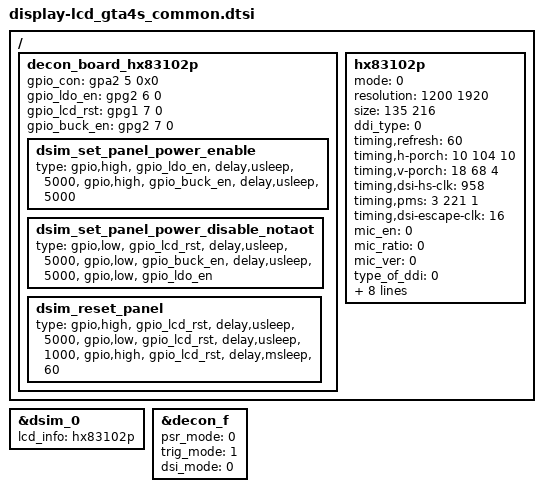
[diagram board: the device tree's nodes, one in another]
/*
 * SAMSUNG LCD Panel Device Tree Source
 *
 * Copyright (c) Samsung Electronics Co., Ltd.
 *		http://www.samsung.com
 *
 * This program is free software; you can redistribute it and/or modify
 * it under the terms of the GNU General Public License version 2 as
 * published by the Free Software Foundation.
 */

/ {
	fragment@lcd {
		target-path = "/";
		__overlay__ {
			decon_board_hx83102p: decon_board_hx83102p {
				gpio_con = <&gpa2 5 0x0>;	/* LCD_CON_DET */

				gpio_ldo_en = <&gpg2 6 0>;
				gpio_lcd_rst = <&gpg1 7 0>;
				gpio_buck_en = <&gpg2 7 0>;

				dsim_set_panel_power_enable {
					type =
					"gpio,high",	"gpio_ldo_en",
					"delay,usleep",	"5000",
					"gpio,high",	"gpio_buck_en",
					"delay,usleep",	"5000";
				};
				dsim_set_panel_power_disable_notaot {
					type =
					"gpio,low",	"gpio_lcd_rst",
					"delay,usleep",	"5000",
					"gpio,low",	"gpio_buck_en",
					"delay,usleep",	"5000",
					"gpio,low",	"gpio_ldo_en";
				};
				dsim_reset_panel {
					type =
					"gpio,high",	"gpio_lcd_rst",
					"delay,usleep",	"5000",
					"gpio,low",	"gpio_lcd_rst",
					"delay,usleep",	"1000",
					"gpio,high",	"gpio_lcd_rst",
					"delay,msleep",	"60";
				};
			};

			hx83102p: hx83102p {
				mode = <0>; /* 0: video mode, 1: DP command mode, 2: MIPI command mode */
				resolution = <1200 1920>;
				size = <135 216>;
				ddi_type = <0>;
				timing,refresh = <60>;
				/* HBP HFP HSW */
				timing,h-porch = <10 104 10>;
				/* VBP VFP VSW */
				timing,v-porch = <18 68 4>;
				timing,dsi-hs-clk = <958>;
				timing,pms = <3 221 1>;
				timing,dsi-escape-clk = <16>;
				mic_en = <0>;		/* 0: Disable, 1: Enable */
				mic_ratio = <0>;	/* 0: 1/2 mic, 1: 1/3 mic */
				mic_ver = <0>;		/* 0: mic v1.1, 1: v1.2, 2: v2.0 */
				type_of_ddi = <0>;	/* 0: Samsung Mobile, 1: MAGNA, 2: Normal(Etc) */
				dsc_en = <0>;		/* 0: Disable, 1: Enable */
				dsc_cnt = <0>;		/* used DSC count */
				dsc_slice_num = <0>;	/* count of dsc slice */
				data_lane = <4>;	/* number of using data lane */
				vt_compensation = <662>;	/* for difference between wordclk and vclk at video mode */
				clklane_onoff = <1>;
				eotp_disabled = <1>;
				decon_board = <&decon_board_hx83102p>;
			};
		};
	};
};

&dsim_0 {
	lcd_info = <&hx83102p>;
};

&decon_f {
	psr_mode = <0>;		/* 0: video mode, 1: DP command mode, 2: MIPI command mode */
	trig_mode = <1>;	/* 0: hw trigger, 1: sw trigger */
	dsi_mode = <0>;		/* 0: single dsi, 1: dual dsi */
};

